# f28004x_dcsm_bank0_z1_regs register map
Vendor: Texas Instruments
Peripheral module from a debugger description file (folder C2000).
Address unit: 16 bits
Registers are 32-bit, read-only, no defined reset value unless marked. A register's access mark holds for its fields unless they carry their own. Offsets are as the file gives them; lines under a group give offsets from that group; [hi:lo] are bit positions; {n}, {i} and the like mark numbered series; 'fields as' and 'values as' point back to an identical list; <NAME> marks a mode.

## DCSM_BANK0_Z1_REGS — DCSM BANK0 Z1 Registers
0x00 B0_Z1_LINKPOINTER_1 — Zone 1 Link Pointer for flash BANK0
  [28:0] LINKPOINTER — Zone1 LINK Pointer for zone Flash BANK0
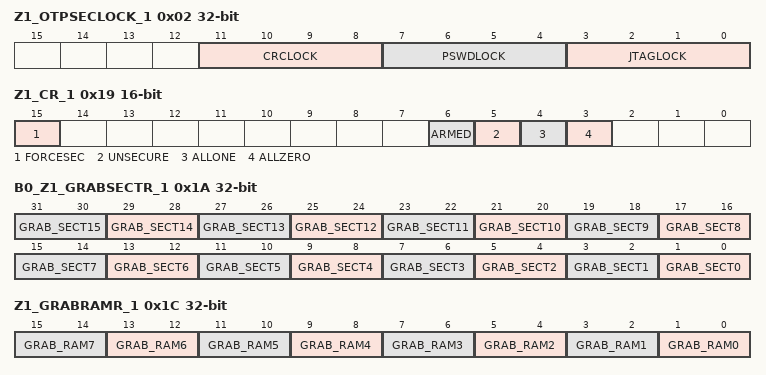
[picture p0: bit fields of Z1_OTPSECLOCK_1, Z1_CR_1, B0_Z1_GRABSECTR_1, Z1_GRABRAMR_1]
0x02 Z1_OTPSECLOCK_1 — Zone 1 OTP Secure JTAG lock
  [11:8] CRCLOCK — Zone1 CRC Lock.
  [7:4] PSWDLOCK — Zone1 Password Lock.
  [3:0] JTAGLOCK — Zone1 JTAG Lock.
0x04 Z1_BOOTDEF_HIGH_1 — Boot definition (high 32bit)
  [31:0] BOOTDEF_HIGH — Boot definition (high) register
0x06 B0_Z1_LINKPOINTERERR_1 — Link Pointer Error for flash BANK0
  [28:0] Z1_LINKPOINTERERR — Error to Resolve Z1 Link pointer from OTP loaded values
0x08 Z1_BOOTPIN_CONFIG_1 — Boot Pin Configuration
  [31:0] BOOTPIN_CONIFG — BOOT Pin configuration
0x0A Z1_GPREG2_1 — Zone1 General Purpose Register-2
  [31:0] GPREG2 — General Purpose Register-2
0x0C Z1_BOOTDEF_LOW_1 — Boot definition (low 32bit)
  [31:0] BOOTDEF_LOW — Boot definition (low) register
0x10 Z1_CSMKEY0_1 — Zone 1 CSM Key 0
  [31:0] Z1_CSMKEY0 — Word0 to unlock Zone1, should match Z1_CSMPSWD0.
{0x10+2i} Z1_CSMKEY{i}_1 (i=1..3) — Zone 1 CSM Key {i}
  [31:0] Z1_CSMKEY{i} — Word{i} to unlock Zone1, should match Z1_CSMPSWD{i}
0x19 Z1_CR_1 16-bit access not given — Zone 1 CSM Control Register
  [15] FORCESEC — Force Secure (access R=0/W)
  [6] ARMED ro — CSM Passwords Read Status
  [5] UNSECURE ro — CSMPSWD Match CSMKEY
  [4] ALLONE ro — CSMPSWD All Ones
  [3] ALLZERO ro — CSMPSWD All Zeros
0x1A B0_Z1_GRABSECTR_1 — Zone 1 Grab Flash BANK0 Sectors Register
  [2n+1:2n] GRAB_SECT{n} (n=0..15) — Grab Flash Sector {n} in BANK0
0x1C Z1_GRABRAMR_1 — Zone 1 Grab RAM Blocks Register
  [2n+1:2n] GRAB_RAM{n} (n=0..7) — Grab RAM LS{n}
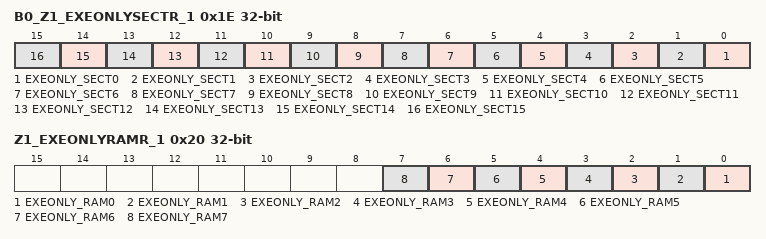
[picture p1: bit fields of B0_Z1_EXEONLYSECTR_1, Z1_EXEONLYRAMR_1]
0x1E B0_Z1_EXEONLYSECTR_1 — Zone 1 Flash BANK0 Execute_Only Sector Register
  [n] EXEONLY_SECT{n} (n=0..15) — Execute-Only Flash Sector {n} in Flash BANK0
0x20 Z1_EXEONLYRAMR_1 — Zone 1 RAM Execute_Only Block Register
  [n] EXEONLY_RAM{n} (n=0..7) — Execute-Only RAM LS{n}
